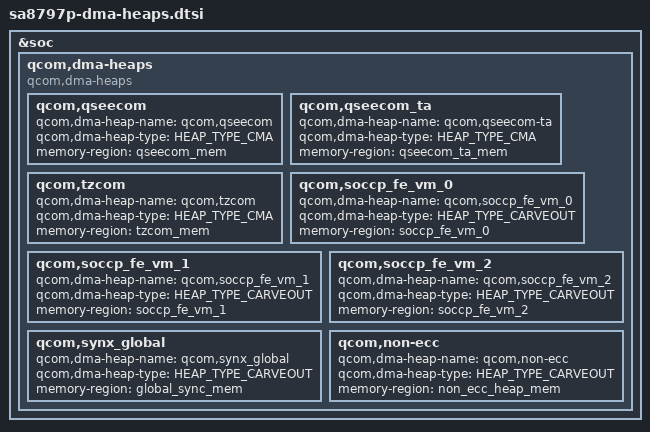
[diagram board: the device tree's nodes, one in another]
// SPDX-License-Identifier: BSD-3-Clause
/*
 * Copyright (c) Qualcomm Technologies, Inc. and/or its subsidiaries.
 */

#include <dt-bindings/arm/qcom_dma_heap_dt_constants.h>

&soc {
	qcom,dma-heaps {
		compatible = "qcom,dma-heaps";

		qcom,qseecom {
			qcom,dma-heap-name = "qcom,qseecom";
			qcom,dma-heap-type = <HEAP_TYPE_CMA>;
			memory-region = <&qseecom_mem>;
		};

		qcom,qseecom_ta {
			qcom,dma-heap-name = "qcom,qseecom-ta";
			qcom,dma-heap-type = <HEAP_TYPE_CMA>;
			memory-region = <&qseecom_ta_mem>;
		};

		qcom,tzcom {
			qcom,dma-heap-name = "qcom,tzcom";
			qcom,dma-heap-type = <HEAP_TYPE_CMA>;
			memory-region = <&tzcom_mem>;
		};

		qcom,soccp_fe_vm_0 {
			qcom,dma-heap-name = "qcom,soccp_fe_vm_0";
			qcom,dma-heap-type = <HEAP_TYPE_CARVEOUT>;
			memory-region = <&soccp_fe_vm_0>;
		};

		qcom,soccp_fe_vm_1 {
			qcom,dma-heap-name = "qcom,soccp_fe_vm_1";
			qcom,dma-heap-type = <HEAP_TYPE_CARVEOUT>;
			memory-region = <&soccp_fe_vm_1>;
		};

		qcom,soccp_fe_vm_2 {
			qcom,dma-heap-name = "qcom,soccp_fe_vm_2";
			qcom,dma-heap-type = <HEAP_TYPE_CARVEOUT>;
			memory-region = <&soccp_fe_vm_2>;
		};

		qcom,synx_global {
			qcom,dma-heap-name = "qcom,synx_global";
			qcom,dma-heap-type = <HEAP_TYPE_CARVEOUT>;
			memory-region = <&global_sync_mem>;
		};

		qcom,non-ecc {
			qcom,dma-heap-name = "qcom,non-ecc";
			qcom,dma-heap-type = <HEAP_TYPE_CARVEOUT>;
			memory-region = <&non_ecc_heap_mem>;
		};
	};
};
